# EZR32HG320F32R67 register map
File version: 5.8.2
CPU: CM0PLUS r0p1, little endian, no MPU, no FPU, 3 interrupt priority bits
Registers are 32-bit, read-write, reset 0x0 unless marked. A register's access mark holds for its fields unless they carry their own. Offsets are from the block's base; [hi:lo] are bit positions; {n}, {i} and the like mark numbered series; 'fields as' and 'values as' point back to an identical list.

## TIMER0
Base 0x40010000
Same registers: TIMER1 0x40010400, TIMER2 0x40010800
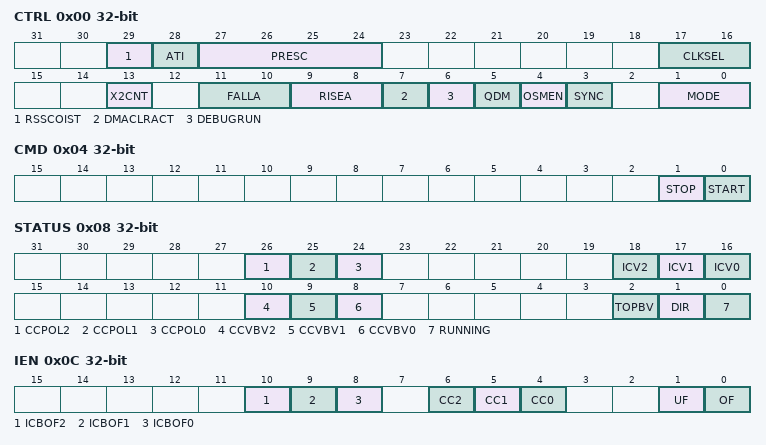
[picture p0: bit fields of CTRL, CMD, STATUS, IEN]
0x00 CTRL — Control Register
  [29] RSSCOIST — Reload-Start Sets Compare Output initial State
  [28] ATI — Always Track Inputs
  [27:24] PRESC — Prescaler Setting
    0=DIV1 (The HFPERCLK is undivided); 1=DIV2 (The HFPERCLK is divided by 2); 2=DIV4 (The HFPERCLK is divided by 4); 3=DIV8 (The HFPERCLK is divided by 8); 4=DIV16 (The HFPERCLK is divided by 16); 5=DIV32 (The HFPERCLK is divided by 32); 6=DIV64 (The HFPERCLK is divided by 64); 7=DIV128 (The HFPERCLK is divided by 128); 8=DIV256 (The HFPERCLK is divided by 256); 9=DIV512 (The HFPERCLK is divided by 512); 10=DIV1024 (The HFPERCLK is divided by 1024)
  [17:16] CLKSEL — Clock Source Select
    0=PRESCHFPERCLK (Prescaled HFPERCLK); 1=CC1 (Compare/Capture Channel 1 Input); 2=TIMEROUF (Timer is clocked by underflow(down-count) or overflow(up-count) in the lower numbered neighbor Timer)
  [13] X2CNT — 2x Count Mode
  [11:10] FALLA — Timer Falling Input Edge Action
    0=NONE (No action); 1=START (Start counter without reload); 2=STOP (Stop counter without reload); 3=RELOADSTART (Reload and start counter)
  [9:8] RISEA — Timer Rising Input Edge Action
    values as FALLA
  [7] DMACLRACT — DMA Request Clear on Active
  [6] DEBUGRUN — Debug Mode Run Enable
  [5] QDM — Quadrature Decoder Mode Selection
  [4] OSMEN — One-shot Mode Enable
  [3] SYNC — Timer Start/Stop/Reload Synchronization
  [1:0] MODE — Timer Mode
    0=UP (Up-count mode); 1=DOWN (Down-count mode); 2=UPDOWN (Up/down-count mode); 3=QDEC (Quadrature decoder mode)
0x04 CMD wo — Command Register
  [1] STOP — Stop Timer
  [0] START — Start Timer
0x08 STATUS ro
  [26] CCPOL2 — CC2 Polarity
  [25] CCPOL1 — CC1 Polarity
  [24] CCPOL0 — CC0 Polarity
  [18] ICV2 — CC2 Input Capture Valid
  [17] ICV1 — CC1 Input Capture Valid
  [16] ICV0 — CC0 Input Capture Valid
  [10] CCVBV2 — CC2 CCVB Valid
  [9] CCVBV1 — CC1 CCVB Valid
  [8] CCVBV0 — CC0 CCVB Valid
  [2] TOPBV — TOPB Valid
  [1] DIR — Direction
  [0] RUNNING
0x0C IEN — Interrupt Enable Register
  [10] ICBOF2 — CC Channel 2 Input Capture Buffer Overflow Interrupt Enable
  [9] ICBOF1 — CC Channel 1 Input Capture Buffer Overflow Interrupt Enable
  [8] ICBOF0 — CC Channel 0 Input Capture Buffer Overflow Interrupt Enable
  [6] CC2 — CC Channel 2 Interrupt Enable
  [5] CC1 — CC Channel 1 Interrupt Enable
  [4] CC0 — CC Channel 0 Interrupt Enable
  [1] UF — Underflow Interrupt Enable
  [0] OF — Overflow Interrupt Enable
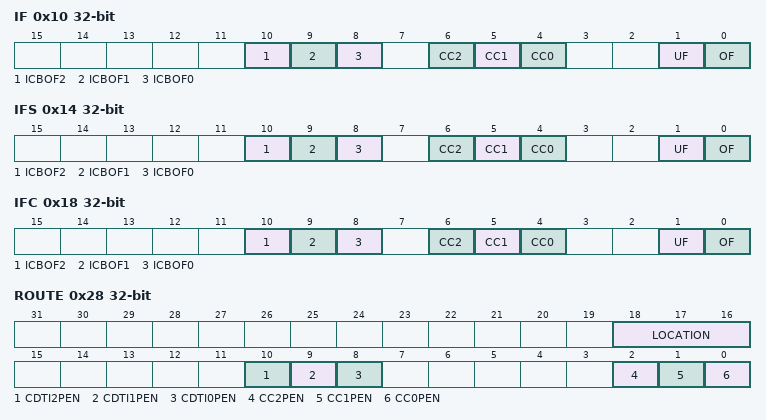
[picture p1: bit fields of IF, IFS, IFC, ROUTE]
0x10 IF ro — Interrupt Flag Register
  [10] ICBOF2 — CC Channel 2 Input Capture Buffer Overflow Interrupt Flag
  [9] ICBOF1 — CC Channel 1 Input Capture Buffer Overflow Interrupt Flag
  [8] ICBOF0 — CC Channel 0 Input Capture Buffer Overflow Interrupt Flag
  [6] CC2 — CC Channel 2 Interrupt Flag
  [5] CC1 — CC Channel 1 Interrupt Flag
  [4] CC0 — CC Channel 0 Interrupt Flag
  [1] UF — Underflow Interrupt Flag
  [0] OF — Overflow Interrupt Flag
0x14 IFS wo — Interrupt Flag Set Register
  [10] ICBOF2 — CC Channel 2 Input Capture Buffer Overflow Interrupt Flag Set
  [9] ICBOF1 — CC Channel 1 Input Capture Buffer Overflow Interrupt Flag Set
  [8] ICBOF0 — CC Channel 0 Input Capture Buffer Overflow Interrupt Flag Set
  [6] CC2 — CC Channel 2 Interrupt Flag Set
  [5] CC1 — CC Channel 1 Interrupt Flag Set
  [4] CC0 — CC Channel 0 Interrupt Flag Set
  [1] UF — Underflow Interrupt Flag Set
  [0] OF — Overflow Interrupt Flag Set
0x18 IFC wo — Interrupt Flag Clear Register
  [10] ICBOF2 — CC Channel 2 Input Capture Buffer Overflow Interrupt Flag Clear
  [9] ICBOF1 — CC Channel 1 Input Capture Buffer Overflow Interrupt Flag Clear
  [8] ICBOF0 — CC Channel 0 Input Capture Buffer Overflow Interrupt Flag Clear
  [6] CC2 — CC Channel 2 Interrupt Flag Clear
  [5] CC1 — CC Channel 1 Interrupt Flag Clear
  [4] CC0 — CC Channel 0 Interrupt Flag Clear
  [1] UF — Underflow Interrupt Flag Clear
  [0] OF — Overflow Interrupt Flag Clear
0x1C TOP reset 0xFFFF — Counter Top Value Register
  [15:0] TOP — Counter Top Value
0x20 TOPB — Counter Top Value Buffer Register
  [15:0] TOPB — Counter Top Value Buffer
0x24 CNT — Counter Value Register
  [15:0] CNT — Counter Value
0x28 ROUTE — I/O Routing Register
  [18:16] LOCATION — I/O Location
    {v}=LOC{v} (Location {v}) (v=0..6)
  [10] CDTI2PEN — CC Channel 2 Complementary Dead-Time Insertion Pin Enable
  [9] CDTI1PEN — CC Channel 1 Complementary Dead-Time Insertion Pin Enable
  [8] CDTI0PEN — CC Channel 0 Complementary Dead-Time Insertion Pin Enable
  [2] CC2PEN — CC Channel 2 Pin Enable
  [1] CC1PEN — CC Channel 1 Pin Enable
  [0] CC0PEN — CC Channel 0 Pin Enable
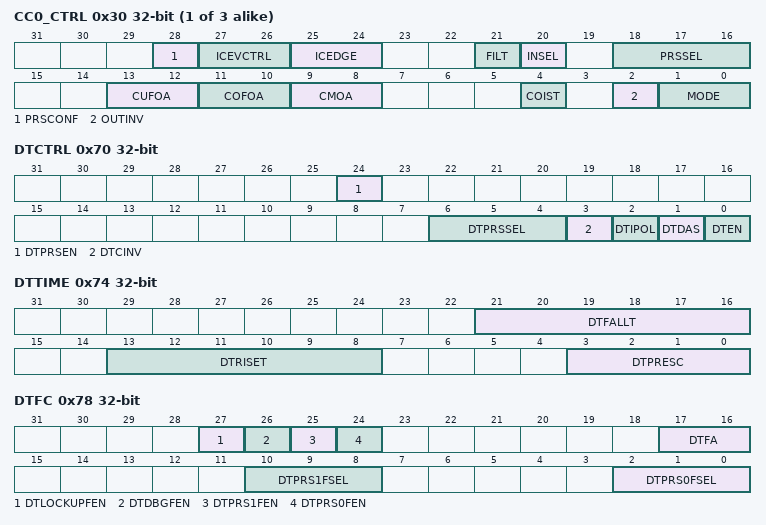
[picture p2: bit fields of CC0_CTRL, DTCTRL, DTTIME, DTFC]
{0x30+0x10*i} CC{i}_CTRL (i=0..2) — CC Channel Control Register
  [28] PRSCONF — PRS Configuration
  [27:26] ICEVCTRL — Input Capture Event Control
    0=EVERYEDGE (PRS output pulse, interrupt flag and DMA request set on every capture); 1=EVERYSECONDEDGE (PRS output pulse, interrupt flag and DMA request set on every second capture); 2=RISING (PRS output pulse, interrupt flag and DMA request set on rising edge only (if ICEDGE = BOTH)); 3=FALLING (PRS output pulse, interrupt flag and DMA request set on falling edge only (if ICEDGE = BOTH))
  [25:24] ICEDGE — Input Capture Edge Select
    0=RISING (Rising edges detected); 1=FALLING (Falling edges detected); 2=BOTH (Both edges detected); 3=NONE (No edge detection, signal is left as it is)
  [21] FILT — Digital Filter
  [20] INSEL — Input Selection
  [18:16] PRSSEL — Compare/Capture Channel PRS Input Channel Selection
    {v}=PRSCH{v} (PRS Channel {v} selected as input) (v=0..5)
  [13:12] CUFOA — Counter Underflow Output Action
    0=NONE (No action on counter underflow); 1=TOGGLE (Toggle output on counter underflow); 2=CLEAR (Clear output on counter underflow); 3=SET (Set output on counter underflow)
  [11:10] COFOA — Counter Overflow Output Action
    0=NONE (No action on counter overflow); 1=TOGGLE (Toggle output on counter overflow); 2=CLEAR (Clear output on counter overflow); 3=SET (Set output on counter overflow)
  [9:8] CMOA — Compare Match Output Action
    0=NONE (No action on compare match); 1=TOGGLE (Toggle output on compare match); 2=CLEAR (Clear output on compare match); 3=SET (Set output on compare match)
  [4] COIST — Compare Output Initial State
  [2] OUTINV — Output Invert
  [1:0] MODE — CC Channel Mode
    0=OFF (Compare/Capture channel turned off); 1=INPUTCAPTURE; 2=OUTPUTCOMPARE; 3=PWM (Pulse-Width Modulation)
{0x34+0x10*i} CC{i}_CCV (i=0..2) — CC Channel Value Register
  [15:0] CCV — CC Channel Value
{0x38+0x10*i} CC{i}_CCVP ro (i=0..2) — CC Channel Value Peek Register
  [15:0] CCVP — CC Channel Value Peek
{0x3C+0x10*i} CC{i}_CCVB (i=0..2) — CC Channel Buffer Register
  [15:0] CCVB — CC Channel Value Buffer
0x70 DTCTRL — DTI Control Register
  [24] DTPRSEN — DTI PRS Source Enable
  [6:4] DTPRSSEL — DTI PRS Source Channel Select
    {v}=PRSCH{v} (PRS Channel {v} selected as input) (v=0..5)
  [3] DTCINV — DTI Complementary Output Invert.
  [2] DTIPOL — DTI Inactive Polarity
  [1] DTDAS — DTI Automatic Start-up Functionality
  [0] DTEN — DTI Enable
0x74 DTTIME — DTI Time Control Register
  [21:16] DTFALLT — DTI Fall-time
  [13:8] DTRISET — DTI Rise-time
  [3:0] DTPRESC — DTI Prescaler Setting
    values as CTRL.PRESC
0x78 DTFC — DTI Fault Configuration Register
  [27] DTLOCKUPFEN — DTI Lockup Fault Enable
  [26] DTDBGFEN — DTI Debugger Fault Enable
  [25] DTPRS1FEN — DTI PRS 1 Fault Enable
  [24] DTPRS0FEN — DTI PRS 0 Fault Enable
  [17:16] DTFA — DTI Fault Action
    0=NONE (No action on fault); 1=INACTIVE (Set outputs inactive); 2=CLEAR (Clear outputs); 3=TRISTATE (Tristate outputs)
  [10:8] DTPRS1FSEL — DTI PRS Fault Source 1 Select
    {v}=PRSCH{v} (PRS Channel {v} selected as fault source 1) (v=0..7)
  [2:0] DTPRS0FSEL — DTI PRS Fault Source 0 Select
    {v}=PRSCH{v} (PRS Channel {v} selected as fault source 0) (v=0..7)
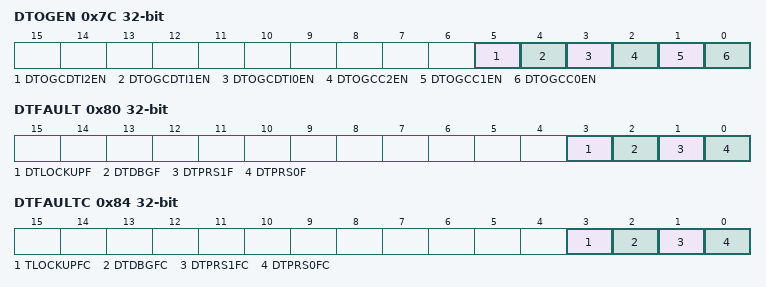
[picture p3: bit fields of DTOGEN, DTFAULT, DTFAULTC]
0x7C DTOGEN — DTI Output Generation Enable Register
  [5] DTOGCDTI2EN — DTI CDTI2 Output Generation Enable
  [4] DTOGCDTI1EN — DTI CDTI1 Output Generation Enable
  [3] DTOGCDTI0EN — DTI CDTI0 Output Generation Enable
  [2] DTOGCC2EN — DTI CC2 Output Generation Enable
  [1] DTOGCC1EN — DTI CC1 Output Generation Enable
  [0] DTOGCC0EN — DTI CC0 Output Generation Enable
0x80 DTFAULT ro — DTI Fault Register
  [3] DTLOCKUPF — DTI Lockup Fault
  [2] DTDBGF — DTI Debugger Fault
  [1] DTPRS1F — DTI PRS 1 Fault
  [0] DTPRS0F — DTI PRS 0 Fault
0x84 DTFAULTC wo — DTI Fault Clear Register
  [3] TLOCKUPFC — DTI Lockup Fault Clear
  [2] DTDBGFC — DTI Debugger Fault Clear
  [1] DTPRS1FC — DTI PRS1 Fault Clear
  [0] DTPRS0FC — DTI PRS0 Fault Clear
0x88 DTLOCK — DTI Configuration Lock Register
  [15:0] LOCKKEY — DTI Lock Key
    0=UNLOCKED; 1=LOCKED

## Notices in the file
# License
Copyright 2019 Silicon Laboratories Inc. www.silabs.com
SPDX-License-Identifier: Zlib
The licensor of this software is Silicon Laboratories Inc.
This software is provided 'as-is', without any express or implied
warranty. In no event will the authors be held liable for any damages
arising from the use of this software.
Permission is granted to anyone to use this software for any purpose,
including commercial applications, and to alter it and redistribute it
freely, subject to the following restrictions:
1. The origin of this software must not be misrepresented; you must not
claim that you wrote the original software. If you use this software
in a product, an acknowledgment in the product documentation would be
appreciated but is not required.
2. Altered source versions must be plainly marked as such, and must not be
misrepresented as being the original software.
3. This notice may not be removed or altered from any source distribution.
